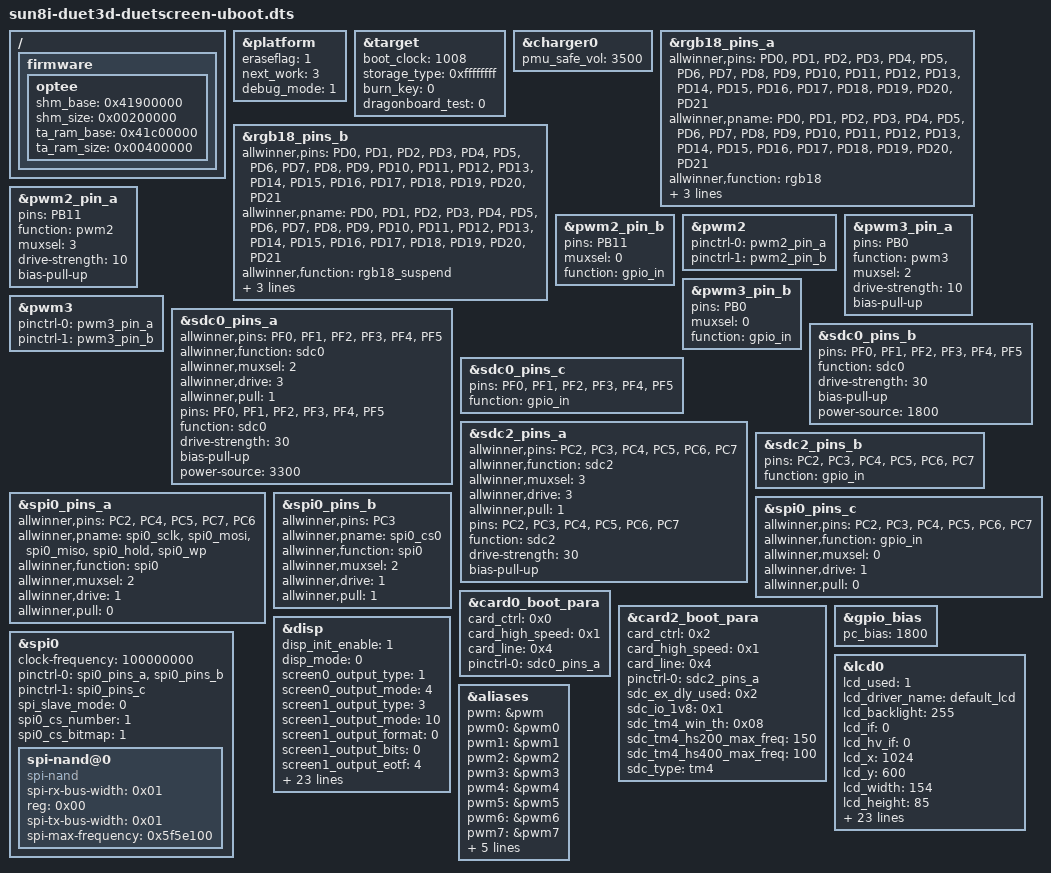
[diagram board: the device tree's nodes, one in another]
/*
 * Allwinner Technology CO., Ltd. sun8iw20p1 soc board.
 *
 * soc board support.
 */

/{
	firmware {
		optee {
			shm_base = <0x41900000>;
			shm_size = <0x00200000>;
			ta_ram_base = <0x41c00000>;
			ta_ram_size = <0x00400000>;
		};
	};
};

&platform {
	eraseflag   = <1>;
	next_work   = <3>;
	debug_mode  = <1>;
};

&target {
	boot_clock = <1008>;	/*CPU boot frequency, Unit: MHz*/
	storage_type = <0xffffffff>; /*boot medium, 0-nand, 1-card0, 2-card2, -1(defualt)auto scan*/
	burn_key = <0>;		/*1:support burn key; 0:not support burn key*/
	dragonboard_test = <0>;	/*1:support card boot dragonboard; 0:not support card boot dragonboard*/
};

&charger0 {
	pmu_safe_vol = <3500>;
};

&rgb18_pins_a {
	allwinner,pins = "PD0", "PD1", "PD2", "PD3", "PD4", "PD5", "PD6", "PD7", "PD8", "PD9", \
	"PD10", "PD11", "PD12", "PD13", "PD14", "PD15", "PD16", "PD17", "PD18", "PD19", \
	"PD20", "PD21";
	allwinner,pname = "PD0", "PD1", "PD2", "PD3", "PD4", "PD5", "PD6", "PD7", "PD8", "PD9", \
	"PD10", "PD11", "PD12", "PD13", "PD14", "PD15", "PD16", "PD17", "PD18", "PD19", \
	"PD20", "PD21";
	allwinner,function = "rgb18";
	allwinner,muxsel = <2>;
	allwinner,drive = <3>;
	allwinner,pull = <0>;
};

&rgb18_pins_b {
	allwinner,pins = "PD0", "PD1", "PD2", "PD3", "PD4", "PD5", "PD6", "PD7", "PD8", "PD9", \
	"PD10", "PD11", "PD12", "PD13", "PD14", "PD15", "PD16", "PD17", "PD18", "PD19", \
	"PD20", "PD21";
	allwinner,pname = "PD0", "PD1", "PD2", "PD3", "PD4", "PD5", "PD6", "PD7", "PD8", "PD9", \
	"PD10", "PD11", "PD12", "PD13", "PD14", "PD15", "PD16", "PD17", "PD18", "PD19", \
	"PD20", "PD21";
	allwinner,function = "rgb18_suspend";
	allwinner,muxsel = <7>;
	allwinner,drive = <1>;
	allwinner,pull = <0>;
};

&pwm2_pin_a {
        pins = "PB11";
        function = "pwm2";
        muxsel = <3>;
        drive-strength = <10>;
        bias-pull-up;
};

&pwm2_pin_b {
        pins = "PB11";
        muxsel = <0>;
        function = "gpio_in";
};

&pwm2 {
        pinctrl-names = "active", "sleep";
        pinctrl-0 = <&pwm2_pin_a>;
        pinctrl-1 = <&pwm2_pin_b>;
        status = "okay";
};

&pwm3_pin_a {
	pins = "PB0";
	function = "pwm3";
	muxsel = <2>;
	drive-strength = <10>;
	bias-pull-up;
};

&pwm3_pin_b {
	pins = "PB0";
	muxsel = <0>;
	function = "gpio_in";
};

&pwm3 {
	pinctrl-names = "active", "sleep";
	pinctrl-0 = <&pwm3_pin_a>;
	pinctrl-1 = <&pwm3_pin_b>;
	status = "okay";
};

&sdc0_pins_a {
	allwinner,pins = "PF0", "PF1", "PF2",
			 "PF3", "PF4", "PF5";
	allwinner,function = "sdc0";
	allwinner,muxsel = <2>;
	allwinner,drive = <3>;
	allwinner,pull = <1>;
	pins = "PF0", "PF1", "PF2", "PF3", "PF4", "PF5";
	function = "sdc0";
	drive-strength = <30>;
	bias-pull-up;
	power-source = <3300>;
};

&sdc0_pins_b {
	pins = "PF0", "PF1", "PF2", "PF3", "PF4", "PF5";
	function = "sdc0";
	drive-strength = <30>;
	bias-pull-up;
	power-source = <1800>;
};

&sdc0_pins_c {
	pins = "PF0", "PF1", "PF2", "PF3", "PF4", "PF5";
	function = "gpio_in";
};

&sdc2_pins_a {
	allwinner,pins = "PC2", "PC3", "PC4", "PC5", "PC6", "PC7";
	allwinner,function = "sdc2";
	allwinner,muxsel = <3>;
	allwinner,drive = <3>;
	allwinner,pull = <1>;
	pins = "PC2", "PC3", "PC4", "PC5", "PC6", "PC7";
	function = "sdc2";
	drive-strength = <30>;
	bias-pull-up;
};

&sdc2_pins_b {
	pins = "PC2", "PC3", "PC4", "PC5", "PC6", "PC7";
	function = "gpio_in";
};

&spi0_pins_a {
	allwinner,pins = "PC2", "PC4", "PC5",
			"PC7", "PC6";
	allwinner,pname = "spi0_sclk", "spi0_mosi",
			"spi0_miso", "spi0_hold", "spi0_wp";
	allwinner,function = "spi0";
	allwinner,muxsel = <2>;
	allwinner,drive = <1>;
	allwinner,pull = <0>;
};

&spi0_pins_b {
	allwinner,pins = "PC3";
	allwinner,pname = "spi0_cs0";
	allwinner,function = "spi0";
	allwinner,muxsel = <2>;
	allwinner,drive = <1>;
	allwinner,pull = <1>;   // only CS should be pulled up
};

&spi0_pins_c {
	allwinner,pins = "PC2", "PC3", "PC4", "PC5",
			"PC6", "PC7";
	allwinner,function = "gpio_in";
	allwinner,muxsel = <0>;
	allwinner,drive = <1>;
	allwinner,pull = <0>;
};

&card0_boot_para {  /* Avoid dtc compiling warnings. @TODO: Developer should modify this to the actual value */
	/* reg = <0x0 0x2 0x0 0x0>;  [> Avoid dtc compiling warnings. @TODO: Developer should modify this to the actual value <] */
	device_type = "card0_boot_para";
	card_ctrl = <0x0>;
	card_high_speed = <0x1>;
	card_line = <0x4>;
	pinctrl-0 = <&sdc0_pins_a>;
};

&card2_boot_para {  /* Avoid dtc compiling warnings. @TODO: Developer should modify this to the actual value */
	/* reg = <0x0 0x3 0x0 0x0>;  [> Avoid dtc compiling warnings. @TODO: Developer should modify this to the actual value <] */
	device_type = "card2_boot_para";
	card_ctrl = <0x2>;
	card_high_speed = <0x1>;
	card_line = <0x4>;
	pinctrl-0 = <&sdc2_pins_a>;
	sdc_ex_dly_used = <0x2>;
	sdc_io_1v8 = <0x1>;
	sdc_tm4_win_th = <0x08>;
	sdc_tm4_hs200_max_freq = <150>;
	sdc_tm4_hs400_max_freq = <100>;
	sdc_type = "tm4";
};
&gpio_bias {  /* Avoid dtc compiling warnings. @TODO: Developer should modify this to the actual value */
	device_type = "gpio_bias";
	pc_bias = <1800>;
};

&spi0 {
	clock-frequency = <100000000>;
	pinctrl-0 = <&spi0_pins_a &spi0_pins_b>;
	pinctrl-1 = <&spi0_pins_c>;
	pinctrl-names = "default", "sleep";
	/*spi-supply = <&reg_dcdc1>;*/
	spi_slave_mode = <0>;
	spi0_cs_number = <1>;
	spi0_cs_bitmap = <1>;
	status = "okay";

	spi-nand@0 {
		compatible = "spi-nand";
		status = "okay";
		spi-rx-bus-width = <0x01>;
		reg = <0x00>;
		spi-tx-bus-width = <0x01>;
		spi-max-frequency = <0x5f5e100>;
	};
};

&disp {
	disp_init_enable         = <1>;
	disp_mode                = <0>;

	screen0_output_type      = <1>;
	screen0_output_mode      = <4>;

	screen1_output_type      = <3>;
	screen1_output_mode      = <10>;

	screen1_output_format    = <0>;
	screen1_output_bits      = <0>;
	screen1_output_eotf      = <4>;
	screen1_output_cs        = <257>;
	screen1_output_dvi_hdmi  = <2>;
	screen1_output_range     = <2>;
	screen1_output_scan      = <0>;
	screen1_output_aspect_ratio = <8>;

	dev0_output_type         = <1>;
	dev0_output_mode         = <4>;
	dev0_screen_id           = <0>;
	dev0_do_hpd              = <0>;

	dev1_output_type         = <4>;
	dev1_output_mode         = <10>;
	dev1_screen_id           = <1>;
	dev1_do_hpd              = <1>;

	def_output_dev           = <0>;
	hdmi_mode_check          = <1>;

	fb0_format               = <0>;
	fb0_width                = <0>;
	fb0_height               = <0>;

	fb1_format               = <0>;
	fb1_width                = <0>;
	fb1_height               = <0>;
	chn_cfg_mode             = <1>;

	disp_para_zone           = <1>;
/*VCC-LCD*/
/*	dc1sw-supply = <&reg_dc1sw>;*/
/*VCC-DSI*/
/*	eldo3-supply = <&reg_eldo3>;*/
/*VCC-PD*/
/*	dcdc1-supply = <&reg_dcdc1>;*/
};

&lcd0 {
	/* part 1 */
	lcd_used            = <1>;
	lcd_driver_name     = "default_lcd";
	lcd_backlight	   = <255>;

	/* part 2 */
	lcd_if = <0>;
	lcd_hv_if = <0>;

	/* part 3 */
	lcd_x               = <1024>;
	lcd_y               = <600>;
	lcd_width           = <154>;
	lcd_height          = <85>;
	lcd_dclk_freq       = <51>;
	lcd_hbp             = <140>;
	lcd_ht              = <1344>;
	lcd_hspw            = <20>;
	lcd_vbp             = <20>;
	lcd_vt              = <635>;
	lcd_vspw            = <3>;

	lcd_pwm_used        = <1>;
	lcd_pwm_ch          = <7>;
	lcd_pwm_freq        = <500>;
	lcd_pwm_pol         = <1>;

	/* part 5 */
	lcd_frm = <1>;
	lcd_io_phase = <0x0000>;
	lcd_gamma_en = <0>;
	lcd_cmap_en = <0>;
	lcd_hv_clk_phase = <0>;
	lcd_hv_sync_polarity= <0>;

	/* part 6 */
	lcd_bl_en_used = <1>;
	lcd_bl_en = <&pio PE 4 GPIO_ACTIVE_HIGH>;
	lcd_power = "vcc-lcd";
	lcd_pin_power = "vcc-pd";
	pinctrl-0 = <&rgb18_pins_a>;
	pinctrl-1 = <&rgb18_pins_b>;
};

&aliases {
	pwm = &pwm;
	pwm0 = &pwm0;
	pwm1 = &pwm1;
	pwm2 = &pwm2;
	pwm3 = &pwm3;
	pwm4 = &pwm4;
	pwm5 = &pwm5;
	pwm6 = &pwm6;
	pwm7 = &pwm7;
	disp = &disp;
	lcd0 = &lcd0;
	lcd1 = &lcd1;
	eink = &eink;
	spi0 = &spi0;
};

